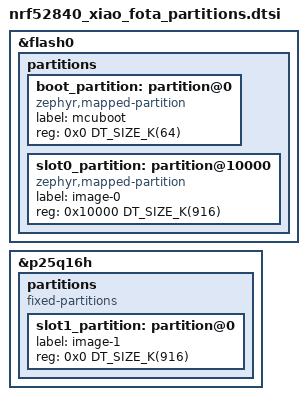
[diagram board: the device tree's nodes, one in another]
#include <nrf52840_partitions.dtsi>

/delete-node/ &slot0_partition;

&flash0 {
	partitions {
		boot_partition: partition@0 {
			compatible = "zephyr,mapped-partition";
			label = "mcuboot";
			reg = <0x0 DT_SIZE_K(64)>;
		};

		slot0_partition: partition@10000 {
			compatible = "zephyr,mapped-partition";
			label = "image-0";
			reg = <0x10000 DT_SIZE_K(916)>;
		};
	};
};

&p25q16h {
	partitions {
		compatible = "fixed-partitions";
		#address-cells = <1>;
		#size-cells = <1>;

		slot1_partition: partition@0 {
			label = "image-1";
			reg = <0x0 DT_SIZE_K(916)>;
		};
	};
};
